# STM32F777 register map
File version: 1.6
CPU: CM7 r0p1, little endian, MPU, FPU, 4 interrupt priority bits
Registers are 32-bit, read-write, reset 0x0 unless marked. A register's access mark holds for its fields unless they carry their own. Offsets are from the block's base; [hi:lo] are bit positions.

## PWR — Power control
Base 0x40007000
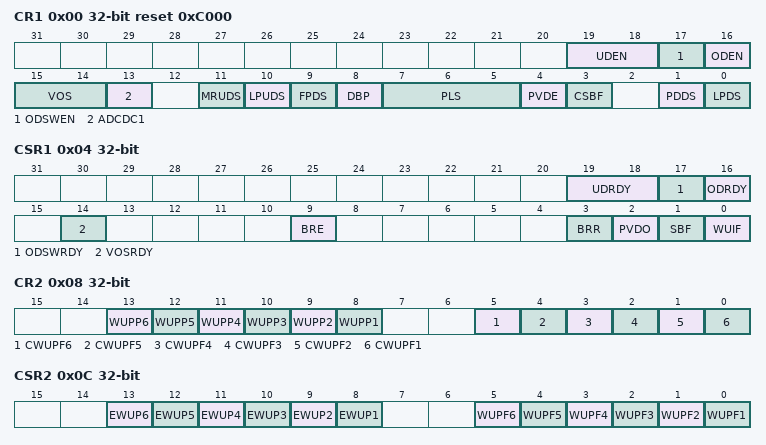
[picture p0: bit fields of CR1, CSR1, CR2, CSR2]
0x00 CR1 reset 0xC000 — power control register
  [19:18] UDEN — Under-drive enable in stop mode
  [17] ODSWEN — Over-drive switching enabled
  [16] ODEN — Over-drive enable
  [15:14] VOS — Regulator voltage scaling output selection
    1=SCALE3 (Scale 3 mode); 2=SCALE2 (Scale 2 mode); 3=SCALE1 (Scale 1 mode (reset value))
  [13] ADCDC1
  [11] MRUDS — Main regulator in deepsleep under-drive mode
  [10] LPUDS — Low-power regulator in deepsleep under-drive mode
  [9] FPDS — Flash power down in Stop mode
  [8] DBP — Disable backup domain write protection
  [7:5] PLS — PVD level selection
  [4] PVDE — Power voltage detector enable
  [3] CSBF — Clear standby flag
  [1] PDDS — Power down deepsleep
    0=STOP_MODE (Enter Stop mode when the CPU enters deepsleep); 1=STANDBY_MODE (Enter Standby mode when the CPU enters deepsleep)
  [0] LPDS — Low-power deep sleep
0x04 CSR1 access per field — power control/status register
  [19:18] UDRDY rw — Under-drive ready flag
  [17] ODSWRDY ro — Over-drive mode switching ready
  [16] ODRDY ro — Over-drive mode ready
  [14] VOSRDY ro — Regulator voltage scaling output selection ready bit
  [9] BRE rw — Backup regulator enable
  [3] BRR ro — Backup regulator ready
  [2] PVDO ro — PVD output
  [1] SBF ro — Standby flag
  [0] WUIF ro — Wakeup internal flag
0x08 CR2 access per field — power control register
  [13] WUPP6 rw — Wakeup pin polarity bit for PI11
  [12] WUPP5 rw — Wakeup pin polarity bit for PI8
  [11] WUPP4 rw — Wakeup pin polarity bit for PC13
  [10] WUPP3 rw — Wakeup pin polarity bit for PC1
  [9] WUPP2 rw — Wakeup pin polarity bit for PA2
  [8] WUPP1 rw — Wakeup pin polarity bit for PA0
  [5] CWUPF6 ro — Clear Wakeup Pin flag for PI11
  [4] CWUPF5 ro — Clear Wakeup Pin flag for PI8
  [3] CWUPF4 ro — Clear Wakeup Pin flag for PC13
  [2] CWUPF3 ro — Clear Wakeup Pin flag for PC1
  [1] CWUPF2 ro — Clear Wakeup Pin flag for PA2
  [0] CWUPF1 ro — Clear Wakeup Pin flag for PA0
0x0C CSR2 access per field — power control/status register
  [13] EWUP6 rw — Enable Wakeup pin for PI11
  [12] EWUP5 rw — Enable Wakeup pin for PI8
  [11] EWUP4 rw — Enable Wakeup pin for PC13
  [10] EWUP3 rw — Enable Wakeup pin for PC1
  [9] EWUP2 rw — Enable Wakeup pin for PA2
  [8] EWUP1 rw — Enable Wakeup pin for PA0
  [5] WUPF6 ro — Wakeup Pin flag for PI11
  [4] WUPF5 ro — Wakeup Pin flag for PI8
  [3] WUPF4 ro — Wakeup Pin flag for PC13
  [2] WUPF3 ro — Wakeup Pin flag for PC1
  [1] WUPF2 ro — Wakeup Pin flag for PA2
  [0] WUPF1 ro — Wakeup Pin flag for PA0

## IWDG — Independent watchdog
Base 0x40003000
0x00 KR 16-bit wo — Key register
  [15:0] KEY — Key value (write only, read 0000h)
    0x5555=Unlock (Enable access to PR, RLR and WINR registers); 0xAAAA=Feed watchdog with RLR register value; 0xCCCC=Start the watchdog
0x04 PR 16-bit — Prescaler register
  [2:0] PR — Prescaler divider
    0=DivideBy4 (Divider /4); 1=DivideBy8 (Divider /8); 2=DivideBy16 (Divider /16); 3=DivideBy32 (Divider /32); 4=DivideBy64 (Divider /64); 5=DivideBy128 (Divider /128); other=DivideBy256 (Divider /256)
0x08 RLR 16-bit reset 0xFFF — Reload register
  [11:0] RL — Watchdog counter reload value
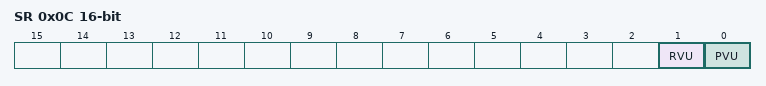
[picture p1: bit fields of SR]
0x0C SR 16-bit ro — Status register
  [1] RVU — Watchdog counter reload value update
  [0] PVU — Watchdog prescaler value update
0x10 WINR 16-bit — Window register
  [11:0] WIN — Watchdog counter window value

## WWDG — Window watchdog
Base 0x40002C00
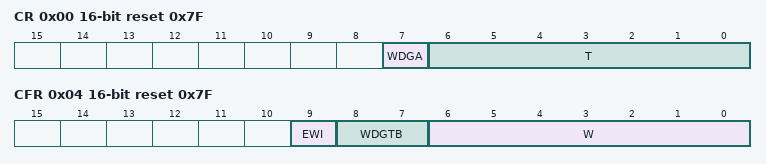
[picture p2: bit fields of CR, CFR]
0x00 CR 16-bit reset 0x7F — Control register
  [7] WDGA — Activation bit
    0=Disabled (Watchdog disabled); 1=Enabled (Watchdog enabled)
  [6:0] T — 7-bit counter (MSB to LSB)
0x04 CFR 16-bit reset 0x7F — Configuration register
  [9] EWI — Early wakeup interrupt
    on write: 1=Enable (interrupt occurs whenever the counter reaches the value 0x40)
  [8:7] WDGTB — Timer base
    0=Div1 (Counter clock (PCLK1 div 4096) div 1); 1=Div2 (Counter clock (PCLK1 div 4096) div 2); 2=Div4 (Counter clock (PCLK1 div 4096) div 4); 3=Div8 (Counter clock (PCLK1 div 4096) div 8)
  [6:0] W — 7-bit window value
0x08 SR 16-bit — Status register
  [0] EWIF write-0-clears — Early wakeup interrupt flag
    on read: 0=Finished (The EWI Interrupt Service Routine has been serviced); 1=Pending (The EWI Interrupt Service Routine has been triggered) | on write: 0=Finished (The EWI Interrupt Service Routine has been serviced)
